# PIC32MX695F512L register map
Registers are 32-bit, access not given, reset 0x0 unless marked. A register's access mark holds for its fields unless they carry their own. Offsets are from the block's base; [hi:lo] are bit positions; 'fields as' and 'values as' point back to an identical list.

## WDT — WDT peripheral
Base 0xBF800000
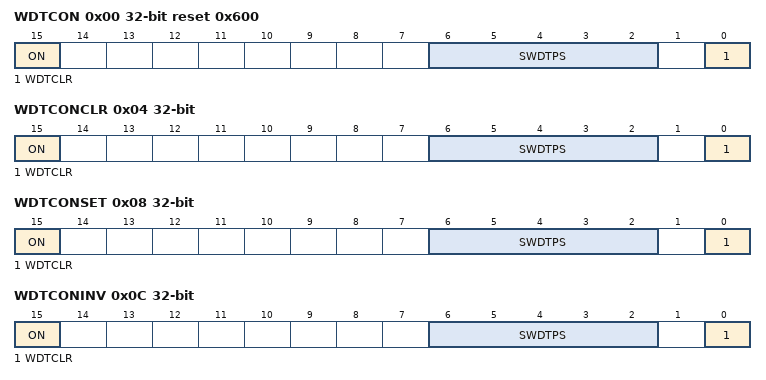
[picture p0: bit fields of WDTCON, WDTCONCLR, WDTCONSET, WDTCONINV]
0x00 WDTCON reset 0x600
  [15] ON, [6:2] SWDTPS, [0] WDTCLR
0x04 WDTCONCLR
  [15] ON, [6:2] SWDTPS, [0] WDTCLR
0x08 WDTCONSET
  [15] ON, [6:2] SWDTPS, [0] WDTCLR
0x0C WDTCONINV
  [15] ON, [6:2] SWDTPS, [0] WDTCLR

## RTCC — RTCC peripheral
Base 0xBF800200
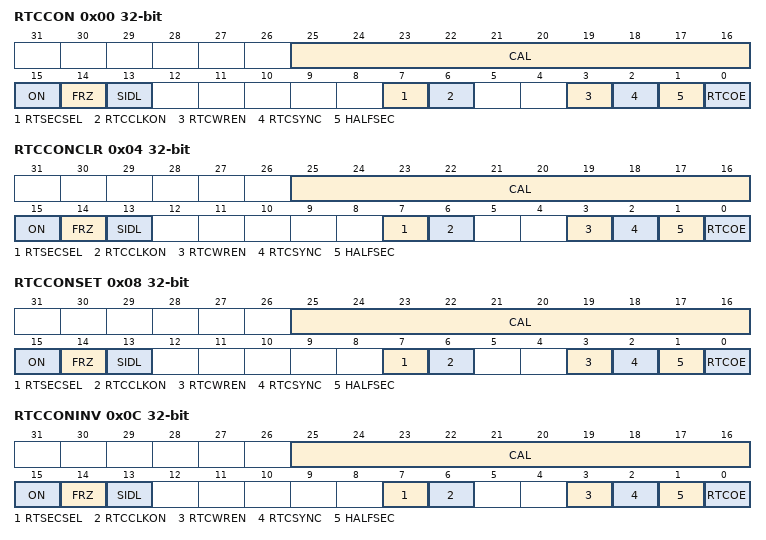
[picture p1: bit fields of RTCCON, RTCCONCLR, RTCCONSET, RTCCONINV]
0x00 RTCCON
  [25:16] CAL, [15] ON, [14] FRZ, [13] SIDL, [7] RTSECSEL, [6] RTCCLKON, [3] RTCWREN, [2] RTCSYNC, [1] HALFSEC, [0] RTCOE
0x04 RTCCONCLR
  fields as RTCCON
0x08 RTCCONSET
  fields as RTCCON
0x0C RTCCONINV
  fields as RTCCON
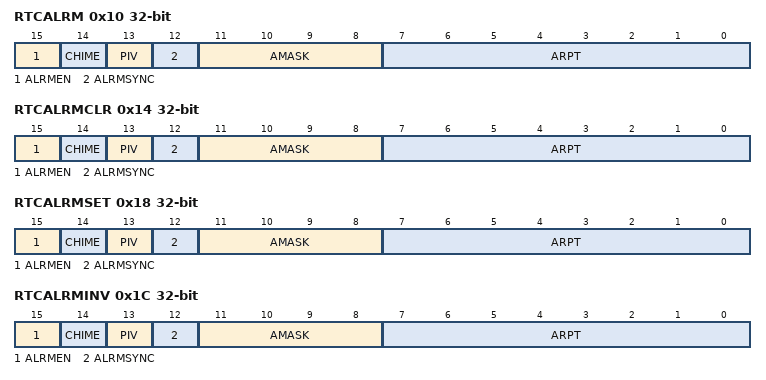
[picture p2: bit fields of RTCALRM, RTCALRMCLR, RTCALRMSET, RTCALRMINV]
0x10 RTCALRM
  [15] ALRMEN, [14] CHIME, [13] PIV, [12] ALRMSYNC, [11:8] AMASK, [7:0] ARPT
0x14 RTCALRMCLR
  fields as RTCALRM
0x18 RTCALRMSET
  fields as RTCALRM
0x1C RTCALRMINV
  fields as RTCALRM
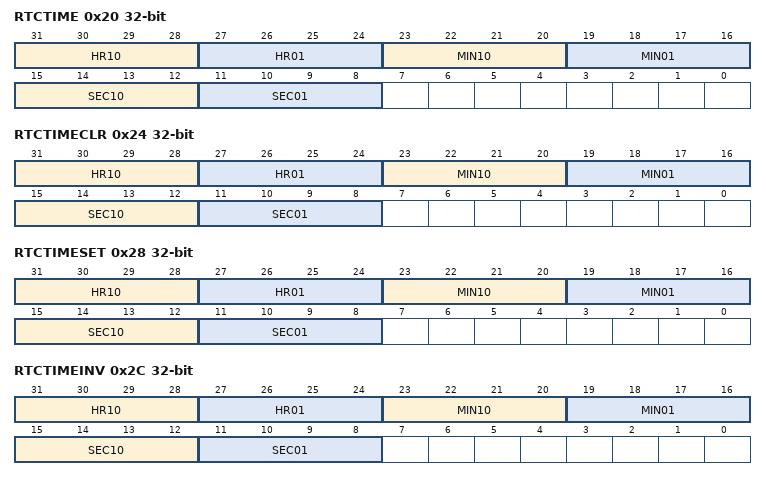
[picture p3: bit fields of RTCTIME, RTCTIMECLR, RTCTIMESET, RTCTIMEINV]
0x20 RTCTIME
  [31:28] HR10, [27:24] HR01, [23:20] MIN10, [19:16] MIN01, [15:12] SEC10, [11:8] SEC01
0x24 RTCTIMECLR
  fields as RTCTIME
0x28 RTCTIMESET
  fields as RTCTIME
0x2C RTCTIMEINV
  fields as RTCTIME
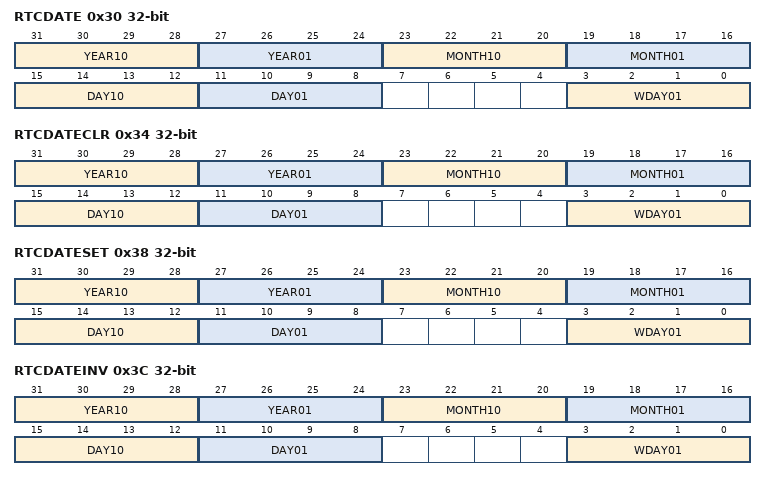
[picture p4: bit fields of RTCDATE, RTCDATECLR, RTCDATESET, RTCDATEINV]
0x30 RTCDATE
  [31:28] YEAR10, [27:24] YEAR01, [23:20] MONTH10, [19:16] MONTH01, [15:12] DAY10, [11:8] DAY01, [3:0] WDAY01
0x34 RTCDATECLR
  fields as RTCDATE
0x38 RTCDATESET
  fields as RTCDATE
0x3C RTCDATEINV
  fields as RTCDATE
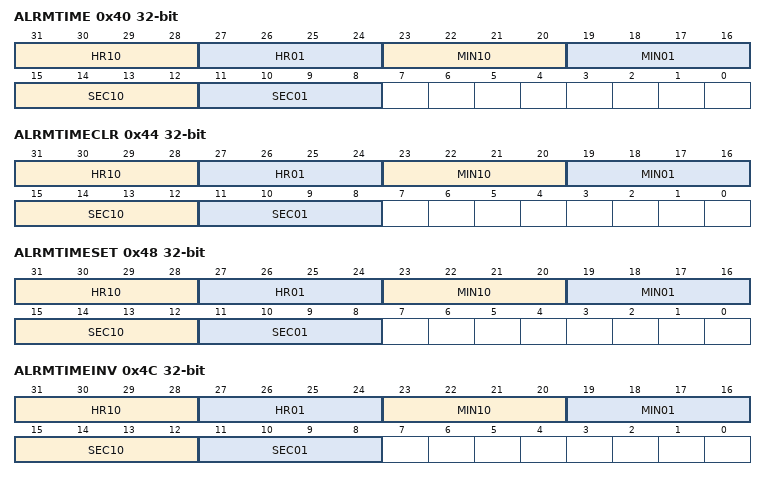
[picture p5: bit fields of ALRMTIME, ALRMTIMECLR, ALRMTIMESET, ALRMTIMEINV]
0x40 ALRMTIME
  fields as RTCTIME
0x44 ALRMTIMECLR
  fields as RTCTIME
0x48 ALRMTIMESET
  fields as RTCTIME
0x4C ALRMTIMEINV
  fields as RTCTIME
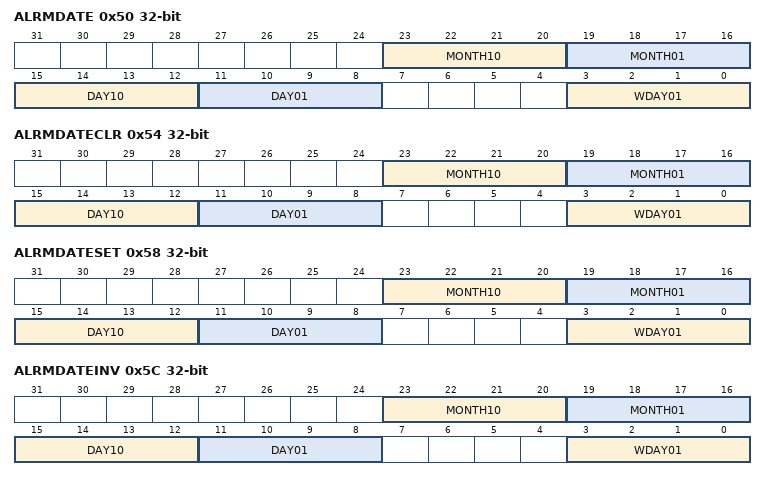
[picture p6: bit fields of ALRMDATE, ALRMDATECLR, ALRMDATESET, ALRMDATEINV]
0x50 ALRMDATE
  [23:20] MONTH10, [19:16] MONTH01, [15:12] DAY10, [11:8] DAY01, [3:0] WDAY01
0x54 ALRMDATECLR
  fields as ALRMDATE
0x58 ALRMDATESET
  fields as ALRMDATE
0x5C ALRMDATEINV
  fields as ALRMDATE

## TMR1 — TMR1 peripheral
Base 0xBF800600
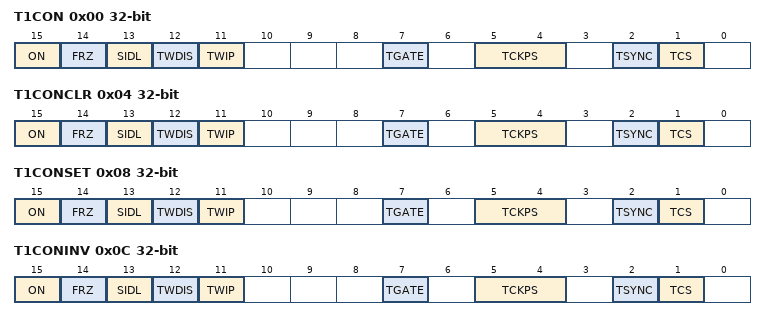
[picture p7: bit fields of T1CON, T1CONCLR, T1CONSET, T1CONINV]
0x00 T1CON
  [15] ON, [14] FRZ, [13] SIDL, [12] TWDIS, [11] TWIP, [7] TGATE, [5:4] TCKPS, [2] TSYNC, [1] TCS
0x04 T1CONCLR
  fields as T1CON
0x08 T1CONSET
  fields as T1CON
0x0C T1CONINV
  fields as T1CON
0x10 TMR1
0x14 TMR1CLR
  [31:0] TMR1
0x18 TMR1SET
  [31:0] TMR1
0x1C TMR1INV
  [31:0] TMR1
0x20 PR1 reset 0xFFFF
0x24 PR1CLR
  [31:0] PR1
0x28 PR1SET
  [31:0] PR1
0x2C PR1INV
  [31:0] PR1

## TMR2 — TMR2 peripheral
Base 0xBF800800
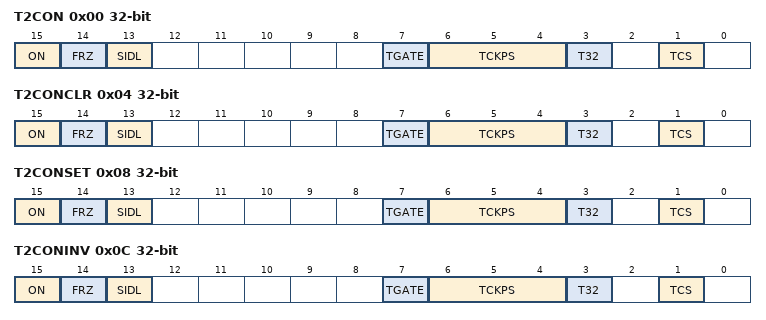
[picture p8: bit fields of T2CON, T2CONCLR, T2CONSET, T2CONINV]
0x00 T2CON
  [15] ON, [14] FRZ, [13] SIDL, [7] TGATE, [6:4] TCKPS, [3] T32, [1] TCS
0x04 T2CONCLR
  fields as T2CON
0x08 T2CONSET
  fields as T2CON
0x0C T2CONINV
  fields as T2CON
0x10 TMR2
0x14 TMR2CLR
  [31:0] TMR2
0x18 TMR2SET
  [31:0] TMR2
0x1C TMR2INV
  [31:0] TMR2
0x20 PR2 reset 0xFFFF
0x24 PR2CLR
  [31:0] PR2
0x28 PR2SET
  [31:0] PR2
0x2C PR2INV
  [31:0] PR2

## TMR3 — TMR3 peripheral
Base 0xBF800A00
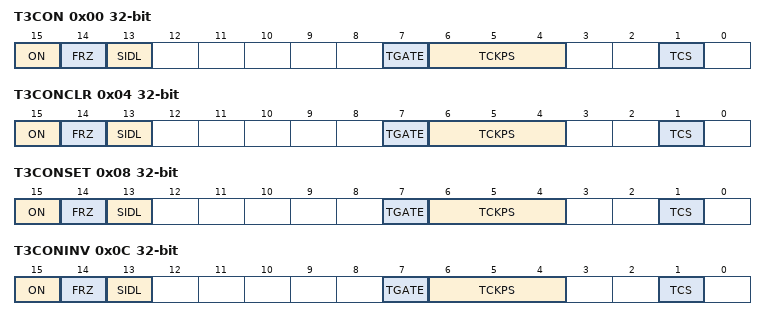
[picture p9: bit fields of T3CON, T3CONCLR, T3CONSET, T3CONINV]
0x00 T3CON
  [15] ON, [14] FRZ, [13] SIDL, [7] TGATE, [6:4] TCKPS, [1] TCS
0x04 T3CONCLR
  [15] ON, [14] FRZ, [13] SIDL, [7] TGATE, [6:4] TCKPS, [1] TCS
0x08 T3CONSET
  [15] ON, [14] FRZ, [13] SIDL, [7] TGATE, [6:4] TCKPS, [1] TCS
0x0C T3CONINV
  [15] ON, [14] FRZ, [13] SIDL, [7] TGATE, [6:4] TCKPS, [1] TCS
0x10 TMR3
0x14 TMR3CLR
  [31:0] TMR3
0x18 TMR3SET
  [31:0] TMR3
0x1C TMR3INV
  [31:0] TMR3
0x20 PR3 reset 0xFFFF
0x24 PR3CLR
  [31:0] PR3
0x28 PR3SET
  [31:0] PR3
0x2C PR3INV
  [31:0] PR3

## TMR4 — TMR4 peripheral
Base 0xBF800C00
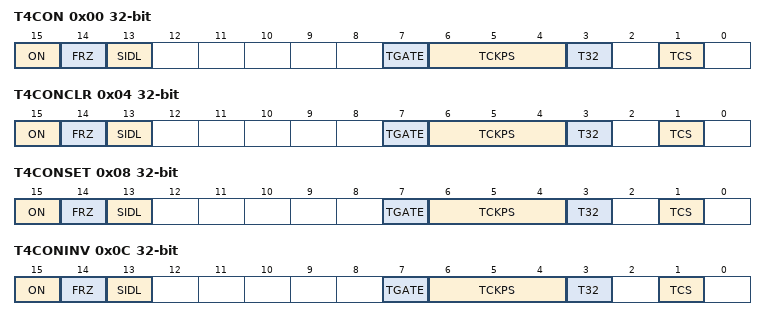
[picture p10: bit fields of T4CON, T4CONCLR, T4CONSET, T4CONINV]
0x00 T4CON
  [15] ON, [14] FRZ, [13] SIDL, [7] TGATE, [6:4] TCKPS, [3] T32, [1] TCS
0x04 T4CONCLR
  fields as T4CON
0x08 T4CONSET
  fields as T4CON
0x0C T4CONINV
  fields as T4CON
0x10 TMR4
0x14 TMR4CLR
  [31:0] TMR4
0x18 TMR4SET
  [31:0] TMR4
0x1C TMR4INV
  [31:0] TMR4
0x20 PR4 reset 0xFFFF
0x24 PR4CLR
  [31:0] PR4
0x28 PR4SET
  [31:0] PR4
0x2C PR4INV
  [31:0] PR4

## TMR5 — TMR5 peripheral
Base 0xBF800E00
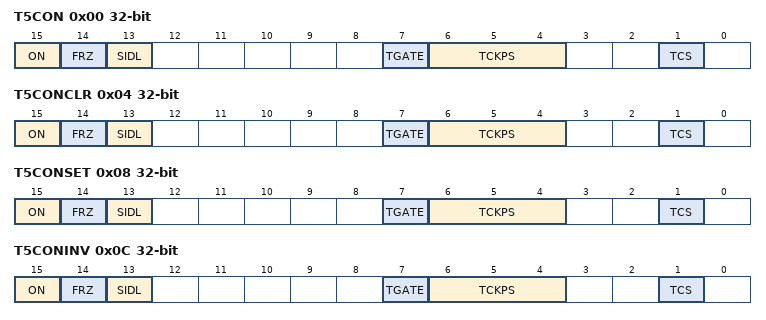
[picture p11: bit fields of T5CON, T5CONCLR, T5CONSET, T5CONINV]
0x00 T5CON
  [15] ON, [14] FRZ, [13] SIDL, [7] TGATE, [6:4] TCKPS, [1] TCS
0x04 T5CONCLR
  [15] ON, [14] FRZ, [13] SIDL, [7] TGATE, [6:4] TCKPS, [1] TCS
0x08 T5CONSET
  [15] ON, [14] FRZ, [13] SIDL, [7] TGATE, [6:4] TCKPS, [1] TCS
0x0C T5CONINV
  [15] ON, [14] FRZ, [13] SIDL, [7] TGATE, [6:4] TCKPS, [1] TCS
0x10 TMR5
0x14 TMR5CLR
  [31:0] TMR5
0x18 TMR5SET
  [31:0] TMR5
0x1C TMR5INV
  [31:0] TMR5
0x20 PR5 reset 0xFFFF
0x24 PR5CLR
  [31:0] PR5
0x28 PR5SET
  [31:0] PR5
0x2C PR5INV
  [31:0] PR5
